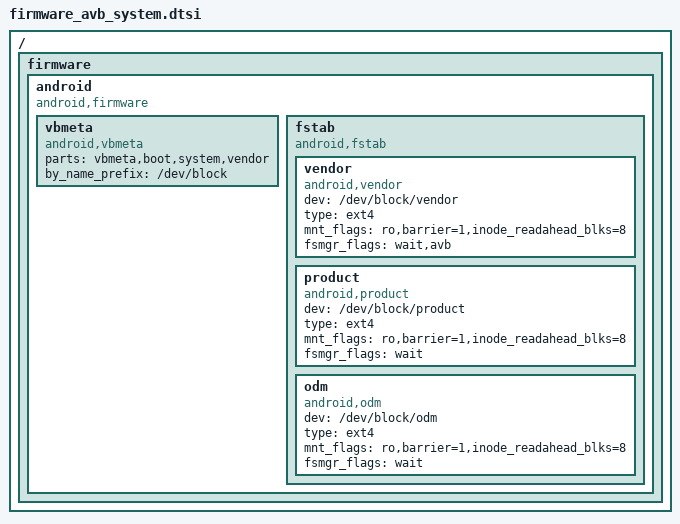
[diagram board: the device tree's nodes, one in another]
/*
 * Amlogic partition set for normal
 *
 * Copyright (c) 2017-2017 Amlogic Ltd
 *
 * This file is licensed under a dual GPLv2 or BSD license.
 *
 */
/ {
	firmware {
		android {
			compatible = "android,firmware";
			vbmeta {
				compatible = "android,vbmeta";
				parts = "vbmeta,boot,system,vendor";
				by_name_prefix="/dev/block";
			};
		fstab {
			compatible = "android,fstab";

			vendor {
				compatible = "android,vendor";
				dev = "/dev/block/vendor";
				type = "ext4";
				mnt_flags = "ro,barrier=1,inode_readahead_blks=8";
				fsmgr_flags = "wait,avb";
				};
			product {
				compatible = "android,product";
				dev = "/dev/block/product";
				type = "ext4";
				mnt_flags = "ro,barrier=1,inode_readahead_blks=8";
				fsmgr_flags = "wait";
				};
			odm {
				compatible = "android,odm";
				dev = "/dev/block/odm";
				type = "ext4";
				mnt_flags = "ro,barrier=1,inode_readahead_blks=8";
				fsmgr_flags = "wait";
				};
			};
		};
	};
};/* end of / */
